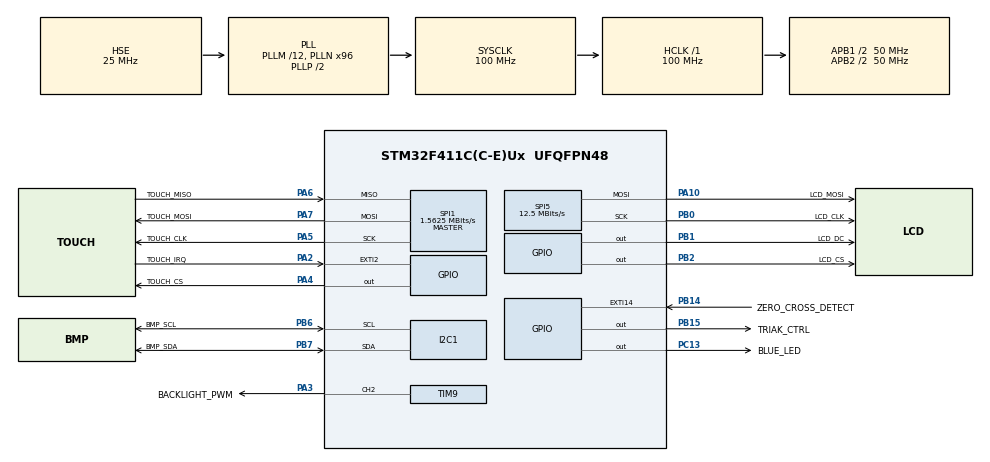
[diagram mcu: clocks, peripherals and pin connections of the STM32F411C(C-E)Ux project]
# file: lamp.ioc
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Mcu.Family=STM32F4
PA6.Mode=Full_Duplex_Master
RCC.CortexFreq_Value=12500000
SPI1.VirtualType=VM_MASTER
PB14.GPIO_Label=ZERO_CROSS_DETECT
PA6.GPIO_Label=TOUCH_MISO
PB0.GPIO_Label=LCD_CLK
PB6.GPIO_Label=BMP_SCL
PB15.Signal=GPIO_Output
RCC.SYSCLKSource=RCC_SYSCLKSOURCE_PLLCLK
ProjectManager.StackSize=0x400
PH0\ -\ OSC_IN.Signal=RCC_OSC_IN
NVIC.TIM5_IRQn=true\:0\:0\:false\:true\:true\:4\:true\:true
SPI1.Direction=SPI_DIRECTION_2LINES
RCC.HCLKFreq_Value=100000000
RCC.APB2TimFreq_Value=100000000
PB6.Signal=I2C1_SCL
PB6.Mode=I2C
SPI1.CalculateBaudRate=1.5625 MBits/s
TIM5.Channel-Output\ Compare4\ No\ Output=TIM_CHANNEL_4
RCC.AHBFreq_Value=100000000
NVIC.EXTI15_10_IRQn=true\:0\:0\:false\:true\:true\:3\:true\:true
RCC.HSE_VALUE=25000000
PB2.Signal=GPIO_Output
PC13-ANTI_TAMP.Signal=GPIO_Output
PC14-OSC32_IN.Mode=LSE-External-Oscillator
TIM3.Prescaler=200
PB1.GPIO_Label=LCD_DC
PA10.GPIO_Label=LCD_MOSI
PB7.Signal=I2C1_SDA
TIM9.Prescaler=1000
PB7.GPIO_Label=BMP_SDA
Mcu.Package=UFQFPN48
SPI5.BaudRatePrescaler=SPI_BAUDRATEPRESCALER_4
PA6.Signal=SPI1_MISO
PB1.Signal=GPIO_Output
PB14.GPIO_PuPd=GPIO_PULLUP
PA2.GPIO_Label=TOUCH_IRQ
PA10.Signal=SPI5_MOSI
SPI5.CalculateBaudRate=12.5 MBits/s
RCC.APB2CLKDivider=RCC_HCLK_DIV2
NVIC.EXTI2_IRQn=true\:0\:0\:false\:true\:true\:2\:true\:true
RCC.APB1TimFreq_Value=100000000
SPI1.BaudRatePrescaler=SPI_BAUDRATEPRESCALER_32
PA4.GPIO_Label=TOUCH_CS
SPI5.VirtualType=VM_MASTER
TIM9.Period=999
PA3.Signal=S_TIM9_CH2
PA5.Mode=Full_Duplex_Master
TIM9.Channel-PWM\ Generation2\ CH2=TIM_CHANNEL_2
PB14.GPIO_ModeDefaultEXTI=GPIO_MODE_IT_FALLING
RCC.PLLSourceVirtual=RCC_PLLSOURCE_HSE
PC15-OSC32_OUT.Mode=LSE-External-Oscillator
PA7.Mode=Full_Duplex_Master
TIM3.Channel-Output\ Compare1\ No\ Output=TIM_CHANNEL_1
PA10.Mode=TX_Only_Simplex_Unidirect_Master
VP_TIM3_VS_no_output3.Mode=Output Compare3 No Output
PC13-ANTI_TAMP.GPIO_Label=BLUE_LED
PH1\ -\ OSC_OUT.Mode=HSE-External-Oscillator
RCC.APB1CLKDivider=RCC_HCLK_DIV2
PC14-OSC32_IN.Signal=RCC_OSC32_IN
SPI5.Mode=SPI_MODE_MASTER
PH0\ -\ OSC_IN.Mode=HSE-External-Oscillator
ProjectManager.TargetToolchain=STM32CubeIDE
SH.S_TIM9_CH2.0=TIM9_CH2,PWM Generation2 CH2
I2C1.I2C_Mode=I2C_Fast
PC15-OSC32_OUT.Signal=RCC_OSC32_OUT
VP_TIM5_VS_no_output4.Mode=Output Compare4 No Output
PB14.Signal=GPXTI14
PA5.Signal=SPI1_SCK
PB0.Mode=TX_Only_Simplex_Unidirect_Master
PH1\ -\ OSC_OUT.Signal=RCC_OSC_OUT
board=custom
VP_TIM3_VS_no_output1.Mode=Output Compare1 No Output
RCC.VCOOutputFreq_Value=200000000
NVIC.TIM3_IRQn=true\:0\:0\:false\:true\:true\:1\:true\:true
RCC.APB2Freq_Value=50000000
PB15.GPIO_Label=TRIAK_CTRL
SPI1.Mode=SPI_MODE_MASTER
Mcu.Name=STM32F411C(C-E)Ux
PA2.Signal=GPXTI2
RCC.48MHZClocksFreq_Value=50000000
TIM3.Channel-Output\ Compare3\ No\ Output=TIM_CHANNEL_3
PA4.Signal=GPIO_Output
RCC.SYSCLKFreq_VALUE=100000000
PA7.GPIO_Label=TOUCH_MOSI
PA5.GPIO_Label=TOUCH_CLK
TIM5.Prescaler=100
PB7.Mode=I2C
PB2.GPIO_Label=LCD_CS
ProjectManager.HeapSize=0x200
RCC.HSI_VALUE=16000000
PA2.GPIO_ModeDefaultEXTI=GPIO_MODE_IT_FALLING
NVIC.PriorityGroup=NVIC_PRIORITYGROUP_4
RCC.PLLM=12
RCC.PLLN=96
TIM5.Period=1000
RCC.Cortex_Div=SYSTICK_CLKSOURCE_HCLK_DIV8
RCC.APB1Freq_Value=50000000
PB0.Signal=SPI5_SCK
SPI5.Direction=SPI_DIRECTION_2LINES
PA3.GPIO_Label=BACKLIGHT_PWM
PA7.Signal=SPI1_MOSI

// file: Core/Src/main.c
/* USER CODE BEGIN Header */
/**
  ******************************************************************************
  * @file           : main.c
  * @brief          : Main program body
  ******************************************************************************
  * @attention
  *
  * <h2><center>&copy; Copyright (c) 2021 STMicroelectronics.
  * All rights reserved.</center></h2>
  *
  * This software component is licensed by ST under BSD 3-Clause license,
  * the "License"; You may not use this file except in compliance with the
  * License. You may obtain a copy of the License at:
  *                        opensource.org/licenses/BSD-3-Clause
  *
  ******************************************************************************
  */
/* USER CODE END Header */
#include "main.h"
#include "i2c.h"
#include "spi.h"
#include "tim.h"
#include "gpio.h"

void SystemClock_Config(void);
static void MX_NVIC_Init(void);

int main(void)
{

  /* MCU Configuration--------------------------------------------------------*/

  /* Reset of all peripherals, Initializes the Flash interface and the Systick. */
  HAL_Init();

  /* Configure the system clock */
  SystemClock_Config();

  /* Initialize all configured peripherals */
  MX_GPIO_Init();
  MX_SPI1_Init();
  MX_SPI5_Init();
  MX_I2C1_Init();
  MX_TIM3_Init();
  MX_TIM9_Init();
  MX_TIM5_Init();

  /* Initialize interrupts */
  MX_NVIC_Init();
  /* USER CODE BEGIN 2 */

  main2();

  /* USER CODE END 2 */

  /* Infinite loop */
  while (1)
  {

  }
}

void SystemClock_Config(void)
{
  RCC_OscInitTypeDef RCC_OscInitStruct = {0};
  RCC_ClkInitTypeDef RCC_ClkInitStruct = {0};

  /** Configure the main internal regulator output voltage
  */
  __HAL_RCC_PWR_CLK_ENABLE();
  __HAL_PWR_VOLTAGESCALING_CONFIG(PWR_REGULATOR_VOLTAGE_SCALE1);
  /** Initializes the RCC Oscillators according to the specified parameters
  * in the RCC_OscInitTypeDef structure.
  */
  RCC_OscInitStruct.OscillatorType = RCC_OSCILLATORTYPE_HSE;
  RCC_OscInitStruct.HSEState = RCC_HSE_ON;
  RCC_OscInitStruct.PLL.PLLState = RCC_PLL_ON;
  RCC_OscInitStruct.PLL.PLLSource = RCC_PLLSOURCE_HSE;
  RCC_OscInitStruct.PLL.PLLM = 12;
  RCC_OscInitStruct.PLL.PLLN = 96;
  RCC_OscInitStruct.PLL.PLLP = RCC_PLLP_DIV2;
  RCC_OscInitStruct.PLL.PLLQ = 4;
  if (HAL_RCC_OscConfig(&RCC_OscInitStruct) != HAL_OK)
  {
    Error_Handler();
  }
  /** Initializes the CPU, AHB and APB buses clocks
  */
  RCC_ClkInitStruct.ClockType = RCC_CLOCKTYPE_HCLK|RCC_CLOCKTYPE_SYSCLK
                              |RCC_CLOCKTYPE_PCLK1|RCC_CLOCKTYPE_PCLK2;
  RCC_ClkInitStruct.SYSCLKSource = RCC_SYSCLKSOURCE_PLLCLK;
  RCC_ClkInitStruct.AHBCLKDivider = RCC_SYSCLK_DIV1;
  RCC_ClkInitStruct.APB1CLKDivider = RCC_HCLK_DIV2;
  RCC_ClkInitStruct.APB2CLKDivider = RCC_HCLK_DIV2;

  if (HAL_RCC_ClockConfig(&RCC_ClkInitStruct, FLASH_LATENCY_3) != HAL_OK)
  {
    Error_Handler();
  }
}

/**
  * @brief NVIC Configuration.
  * @retval None
  */
static void MX_NVIC_Init(void)
{
  /* TIM3_IRQn interrupt configuration */
  HAL_NVIC_SetPriority(TIM3_IRQn, 0, 0);
  HAL_NVIC_EnableIRQ(TIM3_IRQn);
  /* EXTI2_IRQn interrupt configuration */
  HAL_NVIC_SetPriority(EXTI2_IRQn, 0, 0);
  HAL_NVIC_EnableIRQ(EXTI2_IRQn);
  /* EXTI15_10_IRQn interrupt configuration */
  HAL_NVIC_SetPriority(EXTI15_10_IRQn, 0, 0);
  HAL_NVIC_EnableIRQ(EXTI15_10_IRQn);
  /* TIM5_IRQn interrupt configuration */
  HAL_NVIC_SetPriority(TIM5_IRQn, 0, 0);
  HAL_NVIC_EnableIRQ(TIM5_IRQn);
}

void Error_Handler(void)
{
  __disable_irq();
  while (1)
  {
  }
}

/************************ (C) COPYRIGHT STMicroelectronics *****END OF FILE****/
